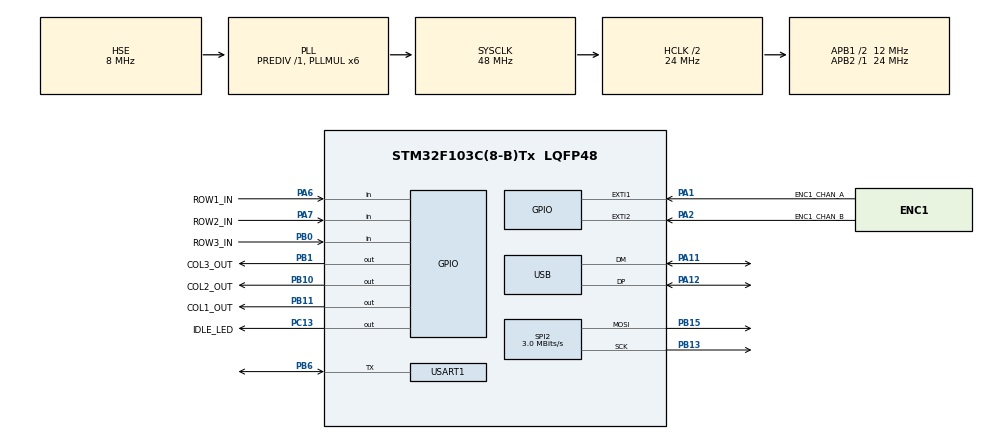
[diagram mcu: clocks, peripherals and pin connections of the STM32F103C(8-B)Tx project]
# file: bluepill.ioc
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Dma.Request0=SPI2_TX
Dma.SPI2_TX.0.Direction=DMA_MEMORY_TO_PERIPH
Dma.SPI2_TX.0.Instance=DMA1_Channel5
Dma.SPI2_TX.0.MemDataAlignment=DMA_MDATAALIGN_BYTE
Dma.SPI2_TX.0.MemInc=DMA_MINC_ENABLE
Dma.SPI2_TX.0.Mode=DMA_NORMAL
Dma.SPI2_TX.0.PeriphDataAlignment=DMA_PDATAALIGN_BYTE
Dma.SPI2_TX.0.PeriphInc=DMA_PINC_DISABLE
Dma.SPI2_TX.0.Priority=DMA_PRIORITY_LOW
Mcu.Family=STM32F1
Mcu.Name=STM32F103C(8-B)Tx
Mcu.Package=LQFP48
NVIC.DMA1_Channel5_IRQn=true\:0\:0\:false\:false\:true\:false\:true
NVIC.EXTI1_IRQn=true\:0\:0\:false\:false\:true\:true\:true
NVIC.EXTI2_IRQn=true\:0\:0\:false\:false\:true\:true\:true
NVIC.PriorityGroup=NVIC_PRIORITYGROUP_4
NVIC.USART1_IRQn=true\:0\:0\:false\:false\:true\:true\:true
NVIC.USB_LP_CAN1_RX0_IRQn=true\:0\:0\:false\:false\:true\:false\:true
PA1.GPIO_Label=ENC1_CHAN_A
PA1.GPIO_ModeDefaultEXTI=GPIO_MODE_IT_RISING_FALLING
PA1.GPIO_PuPd=GPIO_PULLUP
PA1.Signal=GPXTI1
PA11.Mode=Device
PA11.Signal=USB_DM
PA12.Mode=Device
PA12.Signal=USB_DP
PA13.Mode=Serial_Wire
PA13.Signal=SYS_JTMS-SWDIO
PA14.Mode=Serial_Wire
PA14.Signal=SYS_JTCK-SWCLK
PA2.GPIO_Label=ENC1_CHAN_B
PA2.GPIO_ModeDefaultEXTI=GPIO_MODE_IT_RISING_FALLING
PA2.GPIO_PuPd=GPIO_PULLUP
PA2.Signal=GPXTI2
PA6.GPIO_Label=ROW1_IN
PA6.GPIO_PuPd=GPIO_PULLDOWN
PA6.Signal=GPIO_Input
PA7.GPIO_Label=ROW2_IN
PA7.GPIO_PuPd=GPIO_PULLDOWN
PA7.Signal=GPIO_Input
PB0.GPIO_Label=ROW3_IN
PB0.GPIO_PuPd=GPIO_PULLDOWN
PB0.Signal=GPIO_Input
PB1.GPIO_Label=COL3_OUT
PB1.Signal=GPIO_Output
PB10.GPIO_Label=COL2_OUT
PB10.Signal=GPIO_Output
PB11.GPIO_Label=COL1_OUT
PB11.Signal=GPIO_Output
PB13.Mode=TX_Only_Simplex_Unidirect_Master
PB13.Signal=SPI2_SCK
PB15.Mode=TX_Only_Simplex_Unidirect_Master
PB15.Signal=SPI2_MOSI
PB6.Mode=Half_duplex(single_wire_mode)
PB6.Signal=USART1_TX
PC13-TAMPER-RTC.GPIO_Label=IDLE_LED
PC13-TAMPER-RTC.Signal=GPIO_Output
PD0-OSC_IN.Mode=HSE-External-Oscillator
PD0-OSC_IN.Signal=RCC_OSC_IN
PD1-OSC_OUT.Mode=HSE-External-Oscillator
PD1-OSC_OUT.Signal=RCC_OSC_OUT
ProjectManager.HeapSize=0x200
ProjectManager.StackSize=0x400
ProjectManager.TargetToolchain=Makefile
RCC.AHBCLKDivider=RCC_SYSCLK_DIV2
RCC.AHBFreq_Value=24000000
RCC.APB1CLKDivider=RCC_HCLK_DIV2
RCC.APB1Freq_Value=12000000
RCC.APB1TimFreq_Value=24000000
RCC.APB2Freq_Value=24000000
RCC.APB2TimFreq_Value=24000000
RCC.HCLKFreq_Value=24000000
RCC.PLLMUL=RCC_PLL_MUL6
RCC.SYSCLKFreq_VALUE=48000000
RCC.SYSCLKSource=RCC_SYSCLKSOURCE_PLLCLK
RCC.USBFreq_Value=48000000
SPI2.BaudRatePrescaler=SPI_BAUDRATEPRESCALER_4
SPI2.CalculateBaudRate=3.0 MBits/s
SPI2.Direction=SPI_DIRECTION_2LINES
SPI2.Mode=SPI_MODE_MASTER
SPI2.VirtualType=VM_MASTER
USART1.BaudRate=460800
USART1.VirtualMode=VM_ASYNC
USB_DEVICE.CLASS_NAME_FS=HID
USB_DEVICE.MANUFACTURER_STRING=Disciplined Design
USB_DEVICE.PID_HID_FS=0x0666
USB_DEVICE.PRODUCT_STRING_HID_FS=Test Keyboard
USB_DEVICE.VID=0xFEED
USB_DEVICE.VirtualMode=Hid
USB_DEVICE.VirtualModeFS=Hid_FS
VP_USB_DEVICE_VS_USB_DEVICE_HID_FS.Mode=HID_FS
board=bluepill

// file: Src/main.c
/* USER CODE BEGIN Header */
/**
  ******************************************************************************
  * @file           : main.c
  * @brief          : Main program body
  ******************************************************************************
  * @attention
  *
  * <h2><center>&copy; Copyright (c) 2019 STMicroelectronics.
  * All rights reserved.</center></h2>
  *
  * This software component is licensed by ST under BSD 3-Clause license,
  * the "License"; You may not use this file except in compliance with the
  * License. You may obtain a copy of the License at:
  *                        opensource.org/licenses/BSD-3-Clause
  *
  ******************************************************************************
  */
/* USER CODE END Header */

#include "main.h"
#include "usb_device.h"

/* USER CODE BEGIN Includes */
#include "esm/esm.h"
/* USER CODE END Includes */

SPI_HandleTypeDef hspi2;
DMA_HandleTypeDef hdma_spi2_tx;

UART_HandleTypeDef huart1;

/* USER CODE BEGIN PV */
/* Private variables ---------------------------------------------------------*/

/* USER CODE END PV */

void SystemClock_Config(void);
static void MX_GPIO_Init(void);
static void MX_USART1_UART_Init(void);
static void MX_DMA_Init(void);
static void MX_SPI2_Init(void);
/* USER CODE BEGIN PFP */
/* Private function prototypes -----------------------------------------------*/

/* USER CODE END PFP */

int main(void)
{

  /* MCU Configuration--------------------------------------------------------*/

  /* Reset of all peripherals, Initializes the Flash interface and the Systick. */
  HAL_Init();

  /* Configure the system clock */
  SystemClock_Config();

  /* Initialize all configured peripherals */
  MX_GPIO_Init();
  MX_USB_DEVICE_Init();
  MX_USART1_UART_Init();
  MX_DMA_Init();
  MX_SPI2_Init();

  /* Infinite loop */
  /* USER CODE BEGIN WHILE */
  while (1)
  {
	  esm_process();
    /* USER CODE END WHILE */

  }
}

void SystemClock_Config(void)
{
  RCC_OscInitTypeDef RCC_OscInitStruct = {0};
  RCC_ClkInitTypeDef RCC_ClkInitStruct = {0};
  RCC_PeriphCLKInitTypeDef PeriphClkInit = {0};

  /** Initializes the CPU, AHB and APB busses clocks
  */
  RCC_OscInitStruct.OscillatorType = RCC_OSCILLATORTYPE_HSE;
  RCC_OscInitStruct.HSEState = RCC_HSE_ON;
  RCC_OscInitStruct.HSEPredivValue = RCC_HSE_PREDIV_DIV1;
  RCC_OscInitStruct.HSIState = RCC_HSI_ON;
  RCC_OscInitStruct.PLL.PLLState = RCC_PLL_ON;
  RCC_OscInitStruct.PLL.PLLSource = RCC_PLLSOURCE_HSE;
  RCC_OscInitStruct.PLL.PLLMUL = RCC_PLL_MUL6;
  if (HAL_RCC_OscConfig(&RCC_OscInitStruct) != HAL_OK)
  {
    Error_Handler();
  }
  /** Initializes the CPU, AHB and APB busses clocks
  */
  RCC_ClkInitStruct.ClockType = RCC_CLOCKTYPE_HCLK|RCC_CLOCKTYPE_SYSCLK
                              |RCC_CLOCKTYPE_PCLK1|RCC_CLOCKTYPE_PCLK2;
  RCC_ClkInitStruct.SYSCLKSource = RCC_SYSCLKSOURCE_PLLCLK;
  RCC_ClkInitStruct.AHBCLKDivider = RCC_SYSCLK_DIV2;
  RCC_ClkInitStruct.APB1CLKDivider = RCC_HCLK_DIV2;
  RCC_ClkInitStruct.APB2CLKDivider = RCC_HCLK_DIV1;

  if (HAL_RCC_ClockConfig(&RCC_ClkInitStruct, FLASH_LATENCY_1) != HAL_OK)
  {
    Error_Handler();
  }
  PeriphClkInit.PeriphClockSelection = RCC_PERIPHCLK_USB;
  PeriphClkInit.UsbClockSelection = RCC_USBCLKSOURCE_PLL;
  if (HAL_RCCEx_PeriphCLKConfig(&PeriphClkInit) != HAL_OK)
  {
    Error_Handler();
  }
}

static void MX_SPI2_Init(void)
{

  /* SPI2 parameter configuration*/
  hspi2.Instance = SPI2;
  hspi2.Init.Mode = SPI_MODE_MASTER;
  hspi2.Init.Direction = SPI_DIRECTION_2LINES;
  hspi2.Init.DataSize = SPI_DATASIZE_8BIT;
  hspi2.Init.CLKPolarity = SPI_POLARITY_LOW;
  hspi2.Init.CLKPhase = SPI_PHASE_1EDGE;
  hspi2.Init.NSS = SPI_NSS_SOFT;
  hspi2.Init.BaudRatePrescaler = SPI_BAUDRATEPRESCALER_4;
  hspi2.Init.FirstBit = SPI_FIRSTBIT_MSB;
  hspi2.Init.TIMode = SPI_TIMODE_DISABLE;
  hspi2.Init.CRCCalculation = SPI_CRCCALCULATION_DISABLE;
  hspi2.Init.CRCPolynomial = 10;
  if (HAL_SPI_Init(&hspi2) != HAL_OK)
  {
    Error_Handler();
  }

}

static void MX_USART1_UART_Init(void)
{

  huart1.Instance = USART1;
  huart1.Init.BaudRate = 460800;
  huart1.Init.WordLength = UART_WORDLENGTH_8B;
  huart1.Init.StopBits = UART_STOPBITS_1;
  huart1.Init.Parity = UART_PARITY_NONE;
  huart1.Init.Mode = UART_MODE_TX_RX;
  huart1.Init.HwFlowCtl = UART_HWCONTROL_NONE;
  huart1.Init.OverSampling = UART_OVERSAMPLING_16;
  if (HAL_HalfDuplex_Init(&huart1) != HAL_OK)
  {
    Error_Handler();
  }

}

static void MX_DMA_Init(void)
{

  /* DMA controller clock enable */
  __HAL_RCC_DMA1_CLK_ENABLE();

  /* DMA interrupt init */
  /* DMA1_Channel5_IRQn interrupt configuration */
  HAL_NVIC_SetPriority(DMA1_Channel5_IRQn, 0, 0);
  HAL_NVIC_EnableIRQ(DMA1_Channel5_IRQn);

}

static void MX_GPIO_Init(void)
{
  GPIO_InitTypeDef GPIO_InitStruct = {0};

  /* GPIO Ports Clock Enable */
  __HAL_RCC_GPIOC_CLK_ENABLE();
  __HAL_RCC_GPIOD_CLK_ENABLE();
  __HAL_RCC_GPIOA_CLK_ENABLE();
  __HAL_RCC_GPIOB_CLK_ENABLE();

  /*Configure GPIO pin Output Level */
  HAL_GPIO_WritePin(IDLE_LED_GPIO_Port, IDLE_LED_Pin, GPIO_PIN_RESET);

  /*Configure GPIO pin Output Level */
  HAL_GPIO_WritePin(GPIOB, COL3_OUT_Pin|COL2_OUT_Pin|COL1_OUT_Pin, GPIO_PIN_RESET);

  /*Configure GPIO pin : IDLE_LED_Pin */
  GPIO_InitStruct.Pin = IDLE_LED_Pin;
  GPIO_InitStruct.Mode = GPIO_MODE_OUTPUT_PP;
  GPIO_InitStruct.Pull = GPIO_NOPULL;
  GPIO_InitStruct.Speed = GPIO_SPEED_FREQ_LOW;
  HAL_GPIO_Init(IDLE_LED_GPIO_Port, &GPIO_InitStruct);

  /*Configure GPIO pins : ENC1_CHAN_A_Pin ENC1_CHAN_B_Pin */
  GPIO_InitStruct.Pin = ENC1_CHAN_A_Pin|ENC1_CHAN_B_Pin;
  GPIO_InitStruct.Mode = GPIO_MODE_IT_RISING_FALLING;
  GPIO_InitStruct.Pull = GPIO_PULLUP;
  HAL_GPIO_Init(GPIOA, &GPIO_InitStruct);

  /*Configure GPIO pins : ROW1_IN_Pin ROW2_IN_Pin */
  GPIO_InitStruct.Pin = ROW1_IN_Pin|ROW2_IN_Pin;
  GPIO_InitStruct.Mode = GPIO_MODE_INPUT;
  GPIO_InitStruct.Pull = GPIO_PULLDOWN;
  HAL_GPIO_Init(GPIOA, &GPIO_InitStruct);

  /*Configure GPIO pin : ROW3_IN_Pin */
  GPIO_InitStruct.Pin = ROW3_IN_Pin;
  GPIO_InitStruct.Mode = GPIO_MODE_INPUT;
  GPIO_InitStruct.Pull = GPIO_PULLDOWN;
  HAL_GPIO_Init(ROW3_IN_GPIO_Port, &GPIO_InitStruct);

  /*Configure GPIO pins : COL3_OUT_Pin COL2_OUT_Pin COL1_OUT_Pin */
  GPIO_InitStruct.Pin = COL3_OUT_Pin|COL2_OUT_Pin|COL1_OUT_Pin;
  GPIO_InitStruct.Mode = GPIO_MODE_OUTPUT_PP;
  GPIO_InitStruct.Pull = GPIO_NOPULL;
  GPIO_InitStruct.Speed = GPIO_SPEED_FREQ_LOW;
  HAL_GPIO_Init(GPIOB, &GPIO_InitStruct);

  /* EXTI interrupt init*/
  HAL_NVIC_SetPriority(EXTI1_IRQn, 0, 0);
  HAL_NVIC_EnableIRQ(EXTI1_IRQn);

  HAL_NVIC_SetPriority(EXTI2_IRQn, 0, 0);
  HAL_NVIC_EnableIRQ(EXTI2_IRQn);

}

void Error_Handler(void)
{
  while(1)
  {
  }
}

/************************ (C) COPYRIGHT STMicroelectronics *****END OF FILE****/
